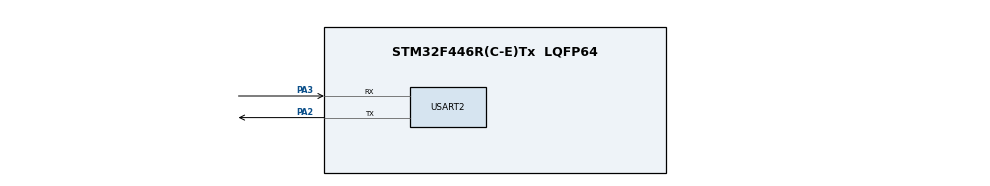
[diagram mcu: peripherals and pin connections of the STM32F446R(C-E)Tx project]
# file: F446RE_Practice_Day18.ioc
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Dma.Request0=USART2_RX
Dma.USART2_RX.0.Direction=DMA_PERIPH_TO_MEMORY
Dma.USART2_RX.0.FIFOMode=DMA_FIFOMODE_DISABLE
Dma.USART2_RX.0.Instance=DMA1_Stream5
Dma.USART2_RX.0.MemDataAlignment=DMA_MDATAALIGN_BYTE
Dma.USART2_RX.0.MemInc=DMA_MINC_ENABLE
Dma.USART2_RX.0.Mode=DMA_CIRCULAR
Dma.USART2_RX.0.PeriphDataAlignment=DMA_PDATAALIGN_BYTE
Dma.USART2_RX.0.PeriphInc=DMA_PINC_DISABLE
Dma.USART2_RX.0.Priority=DMA_PRIORITY_LOW
Mcu.Family=STM32F4
Mcu.Name=STM32F446R(C-E)Tx
Mcu.Package=LQFP64
NVIC.DMA1_Stream5_IRQn=true\:0\:0\:false\:false\:true\:false\:true\:true
NVIC.PriorityGroup=NVIC_PRIORITYGROUP_4
NVIC.USART2_IRQn=true\:0\:0\:false\:false\:true\:true\:true\:true
PA13.Mode=Serial_Wire
PA13.Signal=SYS_JTMS-SWDIO
PA14.Mode=Serial_Wire
PA14.Signal=SYS_JTCK-SWCLK
PA2.Mode=Asynchronous
PA2.Signal=USART2_TX
PA3.Mode=Asynchronous
PA3.Signal=USART2_RX
ProjectManager.HeapSize=0x200
ProjectManager.StackSize=0x400
ProjectManager.TargetToolchain=STM32CubeIDE
RCC.CortexFreq_Value=16000000
RCC.USBFreq_Value=96000000
RCC.VCOOutputFreq_Value=192000000
USART2.VirtualMode=VM_ASYNC
board=custom

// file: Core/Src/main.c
/* USER CODE BEGIN Header */
/**
  ******************************************************************************
  * @file           : main.c
  * @brief          : Main program body
  ******************************************************************************
  * @attention
  *
  * Copyright (c) 2026 STMicroelectronics.
  * All rights reserved.
  *
  * This software is licensed under terms that can be found in the LICENSE file
  * in the root directory of this software component.
  * If no LICENSE file comes with this software, it is provided AS-IS.
  *
  ******************************************************************************
  */
/* USER CODE END Header */
#include "main.h"

/* USER CODE BEGIN Includes */

#include <stdbool.h>
#include <stdint.h>
#include <string.h>

/* USER CODE END Includes */

UART_HandleTypeDef huart2;
DMA_HandleTypeDef hdma_usart2_rx;

/* USER CODE BEGIN PV */

#define UART_DMA_BUFFER_SIZE  64U
#define UART_APP_BUFFER_SIZE  128U

static uint8_t rx_dma_buffer[UART_DMA_BUFFER_SIZE];
static uint8_t app_buffer[UART_APP_BUFFER_SIZE];

volatile uint16_t uart_rx_size = 0U;
volatile bool uart_rx_ready = false;

volatile uint32_t uart_event_count = 0U;
volatile uint32_t uart_overrun_count = 0U;
volatile uint32_t uart_last_event_type = 0U;

/* USER CODE END PV */

void SystemClock_Config(void);
static void MX_GPIO_Init(void);
static void MX_DMA_Init(void);
static void MX_USART2_UART_Init(void);

int main(void)
{

  /* MCU Configuration--------------------------------------------------------*/

  /* Reset of all peripherals, Initializes the Flash interface and the Systick. */
  HAL_Init();

  /* Configure the system clock */
  SystemClock_Config();

  /* Initialize all configured peripherals */
  MX_GPIO_Init();
  MX_DMA_Init();
  MX_USART2_UART_Init();
  /* USER CODE BEGIN 2 */

  HAL_UART_Transmit(&huart2,
                    (uint8_t *)"UART TEST\r\n",
                    11,
                    HAL_MAX_DELAY);

  HAL_UARTEx_ReceiveToIdle_DMA(
      &huart2,
      rx_dma_buffer,
      UART_DMA_BUFFER_SIZE);

  /*
   * 不需要 Half Transfer Event，
   * 今天只處理 IDLE 或 Buffer Full。
   */
  __HAL_DMA_DISABLE_IT(
      huart2.hdmarx,
      DMA_IT_HT);

  /* USER CODE END 2 */

  /* Infinite loop */
  while (1)
  {

    /* USER CODE BEGIN 3 */

	  if (uart_rx_ready)
	    {
	        uint16_t local_size;

	        /*
	         * 短暫保護共享狀態。
	         */
	        __disable_irq();

	        local_size = uart_rx_size;
	        uart_rx_ready = false;

	        __enable_irq();

	        const char prefix[] = "\r\nRX: ";

	        HAL_UART_Transmit(
	            &huart2,
	            (uint8_t *)prefix,
	            sizeof(prefix) - 1U,
	            100U);

	        HAL_UART_Transmit(
	            &huart2,
	            app_buffer,
	            local_size,
	            100U);

	        const char suffix[] = "\r\n";

	        HAL_UART_Transmit(
	            &huart2,
	            (uint8_t *)suffix,
	            sizeof(suffix) - 1U,
	            100U);
	    }

  }
  /* USER CODE END 3 */
}

void SystemClock_Config(void)
{
  RCC_OscInitTypeDef RCC_OscInitStruct = {0};
  RCC_ClkInitTypeDef RCC_ClkInitStruct = {0};

  /** Configure the main internal regulator output voltage
  */
  __HAL_RCC_PWR_CLK_ENABLE();
  __HAL_PWR_VOLTAGESCALING_CONFIG(PWR_REGULATOR_VOLTAGE_SCALE3);

  /** Initializes the RCC Oscillators according to the specified parameters
  * in the RCC_OscInitTypeDef structure.
  */
  RCC_OscInitStruct.OscillatorType = RCC_OSCILLATORTYPE_HSI;
  RCC_OscInitStruct.HSIState = RCC_HSI_ON;
  RCC_OscInitStruct.HSICalibrationValue = RCC_HSICALIBRATION_DEFAULT;
  RCC_OscInitStruct.PLL.PLLState = RCC_PLL_NONE;
  if (HAL_RCC_OscConfig(&RCC_OscInitStruct) != HAL_OK)
  {
    Error_Handler();
  }

  /** Initializes the CPU, AHB and APB buses clocks
  */
  RCC_ClkInitStruct.ClockType = RCC_CLOCKTYPE_HCLK|RCC_CLOCKTYPE_SYSCLK
                              |RCC_CLOCKTYPE_PCLK1|RCC_CLOCKTYPE_PCLK2;
  RCC_ClkInitStruct.SYSCLKSource = RCC_SYSCLKSOURCE_HSI;
  RCC_ClkInitStruct.AHBCLKDivider = RCC_SYSCLK_DIV1;
  RCC_ClkInitStruct.APB1CLKDivider = RCC_HCLK_DIV1;
  RCC_ClkInitStruct.APB2CLKDivider = RCC_HCLK_DIV1;

  if (HAL_RCC_ClockConfig(&RCC_ClkInitStruct, FLASH_LATENCY_0) != HAL_OK)
  {
    Error_Handler();
  }
}

static void MX_USART2_UART_Init(void)
{

  huart2.Instance = USART2;
  huart2.Init.BaudRate = 115200;
  huart2.Init.WordLength = UART_WORDLENGTH_8B;
  huart2.Init.StopBits = UART_STOPBITS_1;
  huart2.Init.Parity = UART_PARITY_NONE;
  huart2.Init.Mode = UART_MODE_TX_RX;
  huart2.Init.HwFlowCtl = UART_HWCONTROL_NONE;
  huart2.Init.OverSampling = UART_OVERSAMPLING_16;
  if (HAL_UART_Init(&huart2) != HAL_OK)
  {
    Error_Handler();
  }

}

static void MX_DMA_Init(void)
{

  /* DMA controller clock enable */
  __HAL_RCC_DMA1_CLK_ENABLE();

  /* DMA interrupt init */
  /* DMA1_Stream5_IRQn interrupt configuration */
  HAL_NVIC_SetPriority(DMA1_Stream5_IRQn, 0, 0);
  HAL_NVIC_EnableIRQ(DMA1_Stream5_IRQn);

}

static void MX_GPIO_Init(void)
{

  /* GPIO Ports Clock Enable */
  __HAL_RCC_GPIOA_CLK_ENABLE();

}

/* USER CODE BEGIN 4 */

void HAL_UARTEx_RxEventCallback(
    UART_HandleTypeDef *huart,
    uint16_t Size)
{
    if (huart->Instance != USART2)
    {
        return;
    }

    uart_event_count++;

    uart_last_event_type =
        (uint32_t)HAL_UARTEx_GetRxEventType(huart);

    /*
     * Demo 版本只允許一次尚未處理的資料。
     * 若前一包還沒處理完，新資料會被計為 Overrun。
     */
    if (uart_rx_ready)
    {
        uart_overrun_count++;
        return;
    }

    if (Size > UART_APP_BUFFER_SIZE)
    {
        Size = UART_APP_BUFFER_SIZE;
    }

    memcpy(
        app_buffer,
        rx_dma_buffer,
        Size);

    uart_rx_size = Size;
    uart_rx_ready = true;
}

/* USER CODE END 4 */

void Error_Handler(void)
{
  __disable_irq();
  while (1)
  {
  }
}
